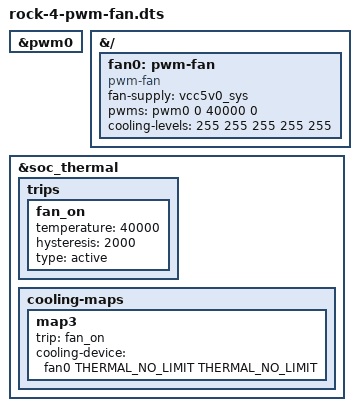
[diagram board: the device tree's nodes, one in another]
/dts-v1/;						
/plugin/;						

#include <dt-bindings/thermal/thermal.h>
#include <dt-bindings/interrupt-controller/arm-gic.h>
#include <dt-bindings/interrupt-controller/irq.h>

/* 	Add an external PWM fan to GPIO pin-11 GPIO4_C2	 (gpio-146) on
	ROCK 4SE & ROCK 4C+ boards
*/

&pwm0 {
    status = "okay";
};

&{/} {
        fan0: pwm-fan {
            compatible = "pwm-fan";
            #cooling-cells = <2>;
            fan-supply = <&vcc5v0_sys>;            
            pwms = <&pwm0 0 40000 0>;
            cooling-levels = <255 255 255 255 255>;
        };
};
    
&soc_thermal {
	/* sustainable-power = <5000>; milliwatts */
	trips {
		fan_on: fan_on {
			temperature = <40000>;
			hysteresis = <2000>;
			type = "active";
		};
	};	

	cooling-maps {
		map3 {
			trip = <&fan_on>;
			cooling-device = <&fan0 THERMAL_NO_LIMIT THERMAL_NO_LIMIT>;
		};
	};
};

